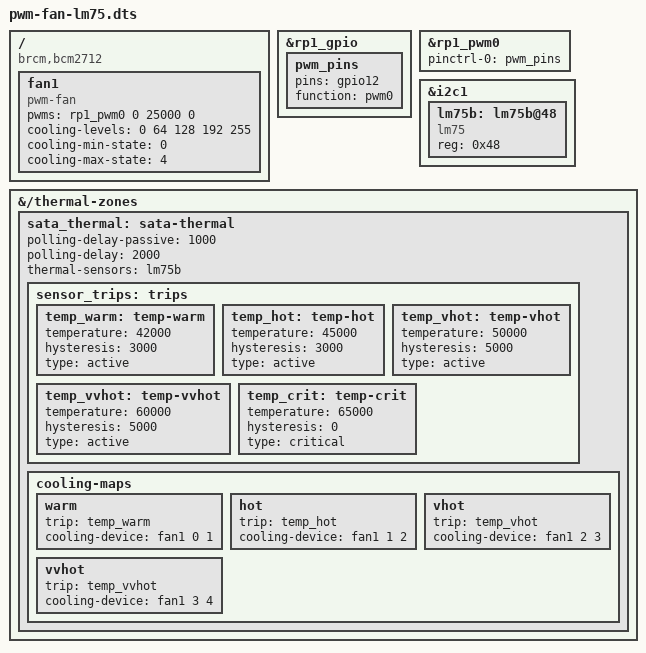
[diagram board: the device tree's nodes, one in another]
/dts-v1/;
/plugin/;
 
/{
    compatible = "brcm,bcm2712";

    fragment@0 {
        target-path = "/";
        __overlay__ {
        
            fan1: fan1 {
                compatible = "pwm-fan";
                pwms = <&rp1_pwm0 0 25000 0>;
                cooling-levels = <0 64 128 192 255>;
                #cooling-cells = <2>;
                cooling-min-state = <0>;
                cooling-max-state = <4>;
            };
        };
    };
    fragment@1 {
        target = <&rp1_gpio>;
        __overlay__ {
            pwm_pins: pwm_pins {
                pins = "gpio12";
                function = "pwm0";
            };
        };
    };
 
    fragment@2 {
        target = <&rp1_pwm0>;
        frag1: __overlay__ {
            pinctrl-names = "default";
            pinctrl-0 = <&pwm_pins>;
            status = "okay";
        };
    };
    fragment@3 {
        target = <&i2c1>;
        __overlay__ {
            #address-cells = <1>;
            #size-cells = <0>;
            status = "okay";

            lm75b: lm75b@48 {
                compatible = "lm75";
                reg = <0x48>;
                status = "okay";
                #thermal-sensor-cells = <0>;
            };
        };
    };
    fragment@4 {
        target-path = "/thermal-zones";
        __overlay__ {
            sata_thermal: sata-thermal {
                polling-delay-passive = <1000>;
                polling-delay = <2000>;
                thermal-sensors = <&lm75b>;
                sensor_trips: trips {
                    temp_warm:temp-warm {
                        temperature = <42000>;
                        hysteresis = <3000>;
                        type = "active";
                    };
                    temp_hot: temp-hot {
                        temperature = <45000>;
                        hysteresis = <3000>;
                        type = "active";
                    };

                    temp_vhot: temp-vhot {
                        temperature = <50000>;
                        hysteresis = <5000>;
                        type = "active";
                    };
                    temp_vvhot: temp-vvhot {
                        temperature = <60000>;
                        hysteresis = <5000>;
                        type = "active";
                    };
		    temp_crit: temp-crit {
			temperature = <65000>; /* millicelsius */
			hysteresis = <0>; /* millicelsius */
			type = "critical";
		    };
                };

                cooling-maps {
                    warm {
                        trip = <&temp_warm>;
                        cooling-device = <&fan1 0 1>;
                    };
                    hot {
                        trip = <&temp_hot>;
                        cooling-device = <&fan1 1 2>;
                    };


                    vhot {
                        trip = <&temp_vhot>;
                        cooling-device = <&fan1 2 3>;
                    };

                    vvhot {
                        trip = <&temp_vvhot>;
                        cooling-device = <&fan1 3 4>;
                    };
                };
            };
        };
    };
    __overrides__ {
      period =		<&fan1>,"pwms:8";
      min_pwm =		<&fan1>,"cooling-levels:4";
      warm_temp =        <&temp_warm>,"temperature:0";
      warm_hyst =        <&temp_warm>,"hysteresis:0";
      hot_temp =	<&temp_hot>,"temperature:0";
      hot_hyst =	<&temp_hot>,"hysteresis:0";
      vhot_temp =	<&temp_vhot>,"temperature:0";
      vhot_hyst =	<&temp_vhot>,"hysteresis:0";
      vvhot_temp =	<&temp_vvhot>,"temperature:0";
    };
};
